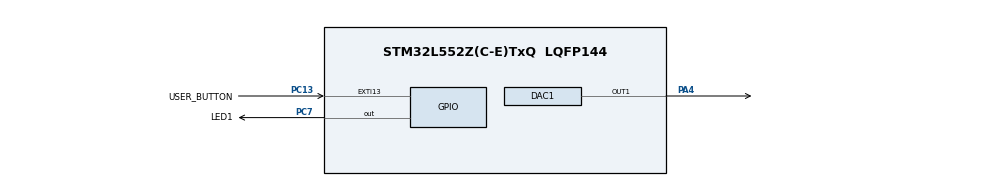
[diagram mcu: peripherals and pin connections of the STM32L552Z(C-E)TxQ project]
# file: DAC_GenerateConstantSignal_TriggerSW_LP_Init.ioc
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DAC1.DAC_HoldTime-DAC_OUT1=(SAMPLE_AND_HOLD_TIMING_HOLD_US    * LSI_FREQUENCY_HZ / 1000000)
DAC1.DAC_RefreshTime-DAC_OUT1=(SAMPLE_AND_HOLD_TIMING_REFRESH_US * LSI_FREQUENCY_HZ / 1000000)
DAC1.DAC_SampleAndHold-DAC_OUT1=DAC_SAMPLEANDHOLD_ENABLE
DAC1.DAC_SampleTime-DAC_OUT1=(SAMPLE_AND_HOLD_TIMING_SAMPLE_US  * LSI_FREQUENCY_HZ / 1000000)
DAC1.DAC_Trigger-DAC_OUT1=DAC_TRIGGER_SOFTWARE
Mcu.Family=STM32L5
Mcu.Name=STM32L552Z(C-E)TxQ
Mcu.Package=LQFP144
Mcu.TrustZone=disable
NVIC.EXTI13_IRQn=true\:3\:0\:true\:false\:true\:true\:true\:true
NVIC.PriorityGroup=NVIC_PRIORITYGROUP_3
PA4.Signal=COMP_DAC11_group
PC13.GPIO_Label=USER_BUTTON
PC13.GPIO_ModeDefaultEXTI=GPIO_MODE_IT_FALLING
PC13.Signal=GPXTI13
PC7.GPIO_Label=LED1
PC7.GPIO_PuPd=GPIO_NOPULL
PC7.Signal=GPIO_Output
ProjectManager.HeapSize=0x200
ProjectManager.StackSize=0x400
ProjectManager.TargetToolchain=EWARM V8.32
RCC.ADCCLockSelection=RCC_ADCCLKSOURCE_SYSCLK
RCC.ADCFreq_Value=110000000
RCC.AHBFreq_Value=110000000
RCC.APB1Freq_Value=110000000
RCC.APB1TimFreq_Value=110000000
RCC.APB2Freq_Value=110000000
RCC.APB2TimFreq_Value=110000000
RCC.CortexFreq_Value=110000000
RCC.HCLKFreq_Value=110000000
RCC.HSE_VALUE=16000000
RCC.HSI48_VALUE=48000000
RCC.HSI_VALUE=16000000
RCC.LSE_VALUE=32768
RCC.MSI_VALUE=4000000
RCC.PLLN=55
RCC.PLLSAI1N=24
RCC.RTCClockSelection=RCC_RTCCLKSOURCE_LSE
RCC.SYSCLKFreq_VALUE=110000000
RCC.SYSCLKSource=RCC_SYSCLKSOURCE_PLLCLK
RCC.USBFreq_Value=48000000
RCC.VCOOutputFreq_Value=220000000
SH.COMP_DAC11_group.0=DAC1_OUT1,DAC_OUT1
VP_ICACHE_VS_ICACHE.Mode=DirectMappedCache
VP_PWR_VS_DBSignals.Mode=DisableDeadBatterySignals
board=custom

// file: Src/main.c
/* USER CODE BEGIN Header */
/**
  ******************************************************************************
  * @file    Examples_LL/DAC/DAC_GenerateConstantSignal_TriggerSW_LP_Init/Src/main.c
  * @author  MCD Application Team
  * @brief   This example describes how to use the DAC peripheral to generate
  *          a constant voltage signal with DAC low power feature
  *          sample-and-hold. To be effective, this mode requires to connect
  *          a capacitor on DAC channel output and sample-and-hold timings
  *          must be tuned in function of capacitor value.
  *          This example is based on the STM32L5xx DAC LL API;
  *          Peripheral initialization done using LL unitary services functions.
  ******************************************************************************
  * @attention
  *
  * Copyright (c) 2019 STMicroelectronics.
  * All rights reserved.
  *
  * This software is licensed under terms that can be found in the LICENSE file
  * in the root directory of this software component.
  * If no LICENSE file comes with this software, it is provided AS-IS.
  *
  ******************************************************************************
  */
/* USER CODE END Header */
#include "main.h"

/* USER CODE BEGIN PD */
/* Definitions of environment analog values */
  /* Value of analog reference voltage (Vref+), connected to analog voltage   */
  /* supply Vdda (unit: mV).                                                  */
  #define VDDA_APPLI                       ((uint32_t)3300)

/* Definitions of data related to this example */
  /* Full-scale digital value with a resolution of 12 bits (voltage range     */
  /* determined by analog voltage references Vref+ and Vref-,                 */
  /* refer to reference manual).                                              */
  #define DIGITAL_SCALE_12BITS             (__LL_DAC_DIGITAL_SCALE(LL_DAC_RESOLUTION_12B))

/* Definitions of data related to DAC low power mode sample-and-hold */
  /* LSI frequency (unit: Hertz) */
  #define LSI_FREQUENCY_HZ                   ((uint32_t)32000)

  /* Definitions of DAC mode sample-and-hold timings (unit: micro-seconds)    */
  /* Note: Timings are set to an arbitrary value, in a real application       */
  /*       they should be tuned in function of capacitor value connected      */
  /*       to DAC output (refer to reference manual).                         */
  /*       If no capacitor is connected on DAC channel output or if           */
  /*       inappropriate timings are set, the voltage appears as              */
  /*       discontinuous.                                                     */
  #define SAMPLE_AND_HOLD_TIMING_SAMPLE_US   ((uint32_t)6000)
  #define SAMPLE_AND_HOLD_TIMING_HOLD_US     ((uint32_t)2000)
  #define SAMPLE_AND_HOLD_TIMING_REFRESH_US  ((uint32_t)5000)

/* USER CODE END PD */

/* USER CODE BEGIN PV */
__IO uint8_t ubButtonPress = 0;
__IO uint8_t ubButtonPressCount = 0;
/* USER CODE END PV */

void SystemClock_Config(void);
static void MX_GPIO_Init(void);
static void MX_ICACHE_Init(void);
static void MX_DAC1_Init(void);
/* USER CODE BEGIN PFP */
void     Activate_DAC(void);
void     LED_On(void);
void     LED_Off(void);
void     LED_Toggle(void);
void     LED_Blinking(uint32_t Period);
void     WaitForUserButtonPress(void);

/* USER CODE END PFP */

int main(void)
{

  /* MCU Configuration--------------------------------------------------------*/

  /* Reset of all peripherals, Initializes the Flash interface and the Systick. */
  LL_APB2_GRP1_EnableClock(LL_APB2_GRP1_PERIPH_SYSCFG);
  LL_APB1_GRP1_EnableClock(LL_APB1_GRP1_PERIPH_PWR);

  /* System interrupt init*/
  NVIC_SetPriorityGrouping(NVIC_PRIORITYGROUP_3);

  /** Disable the internal Pull-Up in Dead Battery pins of UCPD peripheral
  */
  LL_PWR_DisableUCPDDeadBattery();

  /* Configure the system clock */
  SystemClock_Config();

  /* Initialize all configured peripherals */
  MX_GPIO_Init();
  MX_ICACHE_Init();
  MX_DAC1_Init();
  /* USER CODE BEGIN 2 */
/* Wait for User push-button press */
  WaitForUserButtonPress();

  /* Turn-off LED1 */
  LED_Off();

  /* Enable LSI (required for DAC mode sample-and-hold) */
  LL_RCC_LSI_Enable();

  /* Activate DAC channel */
  Activate_DAC();

  /* Turn-on LED1 */
  LED_On();
  /* USER CODE END 2 */

  /* Infinite loop */
  /* USER CODE BEGIN WHILE */
  while (1)
  {
    /* Note: LED state depending and DAC channel output are set into          */
    /*       function "UserButton_Callback()".                                */
    /* USER CODE END WHILE */

  }
}

void SystemClock_Config(void)
{
  LL_FLASH_SetLatency(LL_FLASH_LATENCY_5);
  while(LL_FLASH_GetLatency()!= LL_FLASH_LATENCY_5)
  {
  }

  LL_PWR_SetRegulVoltageScaling(LL_PWR_REGU_VOLTAGE_SCALE0);
  LL_RCC_LSI_Enable();

   /* Wait till LSI is ready */
  while(LL_RCC_LSI_IsReady() != 1)
  {
  }

  LL_RCC_MSI_Enable();

   /* Wait till MSI is ready */
  while(LL_RCC_MSI_IsReady() != 1)
  {
  }

  LL_RCC_MSI_EnableRangeSelection();
  LL_RCC_MSI_SetRange(LL_RCC_MSIRANGE_6);
  LL_RCC_MSI_SetCalibTrimming(0);
  LL_RCC_PLL_ConfigDomain_SYS(LL_RCC_PLLSOURCE_MSI, LL_RCC_PLLM_DIV_1, 55, LL_RCC_PLLR_DIV_2);
  LL_RCC_PLL_EnableDomain_SYS();
  LL_RCC_PLL_Enable();

   /* Wait till PLL is ready */
  while(LL_RCC_PLL_IsReady() != 1)
  {
  }

   /* Intermediate AHB prescaler 2 when target frequency clock is higher than 80 MHz */
   LL_RCC_SetAHBPrescaler(LL_RCC_SYSCLK_DIV_2);

  LL_RCC_SetSysClkSource(LL_RCC_SYS_CLKSOURCE_PLL);

   /* Wait till System clock is ready */
  while(LL_RCC_GetSysClkSource() != LL_RCC_SYS_CLKSOURCE_STATUS_PLL)
  {
  }

  /* Insure 1us transition state at intermediate medium speed clock*/
  for (__IO uint32_t i = (RCC_MAX_FREQUENCY_MHZ >> 1); i !=0; i--);

  LL_RCC_SetAHBPrescaler(LL_RCC_SYSCLK_DIV_1);
  LL_RCC_SetAPB1Prescaler(LL_RCC_APB1_DIV_1);
  LL_RCC_SetAPB2Prescaler(LL_RCC_APB2_DIV_1);

  LL_Init1msTick(110000000);

  LL_SetSystemCoreClock(110000000);
}

static void MX_DAC1_Init(void)
{

  LL_DAC_InitTypeDef DAC_InitStruct = {0};

  LL_GPIO_InitTypeDef GPIO_InitStruct = {0};

  /* Peripheral clock enable */
  LL_APB1_GRP1_EnableClock(LL_APB1_GRP1_PERIPH_DAC1);

  LL_AHB2_GRP1_EnableClock(LL_AHB2_GRP1_PERIPH_GPIOA);
  /**DAC1 GPIO Configuration
  PA4   ------> DAC1_OUT1
  */
  GPIO_InitStruct.Pin = LL_GPIO_PIN_4;
  GPIO_InitStruct.Mode = LL_GPIO_MODE_ANALOG;
  GPIO_InitStruct.Pull = LL_GPIO_PULL_NO;
  LL_GPIO_Init(GPIOA, &GPIO_InitStruct);

  /** DAC channel OUT1 config
  */
  DAC_InitStruct.TriggerSource = LL_DAC_TRIG_SOFTWARE;
  DAC_InitStruct.WaveAutoGeneration = LL_DAC_WAVE_AUTO_GENERATION_NONE;
  DAC_InitStruct.OutputBuffer = LL_DAC_OUTPUT_BUFFER_ENABLE;
  DAC_InitStruct.OutputConnection = LL_DAC_OUTPUT_CONNECT_GPIO;
  DAC_InitStruct.OutputMode = LL_DAC_OUTPUT_MODE_SAMPLE_AND_HOLD;
  LL_DAC_Init(DAC1, LL_DAC_CHANNEL_1, &DAC_InitStruct);
  LL_DAC_EnableTrigger(DAC1, LL_DAC_CHANNEL_1);
  LL_DAC_SetSampleAndHoldSampleTime(DAC1, LL_DAC_CHANNEL_1, (SAMPLE_AND_HOLD_TIMING_SAMPLE_US * LSI_FREQUENCY_HZ / 1000000));
  LL_DAC_SetSampleAndHoldHoldTime(DAC1, LL_DAC_CHANNEL_1, (SAMPLE_AND_HOLD_TIMING_HOLD_US * LSI_FREQUENCY_HZ / 1000000));
  LL_DAC_SetSampleAndHoldRefreshTime(DAC1, LL_DAC_CHANNEL_1, (SAMPLE_AND_HOLD_TIMING_REFRESH_US * LSI_FREQUENCY_HZ / 1000000));

}

static void MX_ICACHE_Init(void)
{

  /** Enable instruction cache in 1-way (direct mapped cache)
  */
  LL_ICACHE_SetMode(LL_ICACHE_1WAY);
  LL_ICACHE_Enable();

}

static void MX_GPIO_Init(void)
{
  LL_EXTI_InitTypeDef EXTI_InitStruct = {0};
  LL_GPIO_InitTypeDef GPIO_InitStruct = {0};

  /* GPIO Ports Clock Enable */
  LL_AHB2_GRP1_EnableClock(LL_AHB2_GRP1_PERIPH_GPIOC);
  LL_AHB2_GRP1_EnableClock(LL_AHB2_GRP1_PERIPH_GPIOA);

  /**/
  LL_GPIO_ResetOutputPin(LED1_GPIO_Port, LED1_Pin);

  /**/
  LL_EXTI_SetEXTISource(LL_EXTI_EXTI_PORTC, LL_EXTI_EXTI_LINE13);

  /**/
  EXTI_InitStruct.Line_0_31 = LL_EXTI_LINE_13;
  EXTI_InitStruct.Line_32_63 = LL_EXTI_LINE_NONE;
  EXTI_InitStruct.LineCommand = ENABLE;
  EXTI_InitStruct.Mode = LL_EXTI_MODE_IT;
  EXTI_InitStruct.Trigger = LL_EXTI_TRIGGER_FALLING;
  LL_EXTI_Init(&EXTI_InitStruct);

  /**/
  LL_GPIO_SetPinPull(USER_BUTTON_GPIO_Port, USER_BUTTON_Pin, LL_GPIO_PULL_NO);

  /**/
  LL_GPIO_SetPinMode(USER_BUTTON_GPIO_Port, USER_BUTTON_Pin, LL_GPIO_MODE_INPUT);

  /**/
  GPIO_InitStruct.Pin = LED1_Pin;
  GPIO_InitStruct.Mode = LL_GPIO_MODE_OUTPUT;
  GPIO_InitStruct.Speed = LL_GPIO_SPEED_FREQ_LOW;
  GPIO_InitStruct.OutputType = LL_GPIO_OUTPUT_PUSHPULL;
  GPIO_InitStruct.Pull = LL_GPIO_PULL_NO;
  LL_GPIO_Init(LED1_GPIO_Port, &GPIO_InitStruct);

  /* EXTI interrupt init*/
  NVIC_SetPriority(EXTI13_IRQn, NVIC_EncodePriority(NVIC_GetPriorityGrouping(),3, 0));
  NVIC_EnableIRQ(EXTI13_IRQn);

}

/* USER CODE BEGIN 4 */

/**
  * @brief  Perform DAC activation procedure to make it ready to generate
  *         a voltage (DAC instance: DAC1).
  * @note   Operations:
  *         - Enable DAC instance channel
  *         - Wait for DAC instance channel startup time
  * @param  None
  * @retval None
  */
void Activate_DAC(void)
{
  __IO uint32_t wait_loop_index = 0;

  /* Enable DAC channel */
  LL_DAC_Enable(DAC1, LL_DAC_CHANNEL_1);

  /* Delay for DAC channel voltage settling time from DAC channel startup.    */
  /* Compute number of CPU cycles to wait for, from delay in us.              */
  /* Note: Variable divided by 2 to compensate partially                      */
  /*       CPU processing cycles (depends on compilation optimization).       */
  /* Note: If system core clock frequency is below 200kHz, wait time          */
  /*       is only a few CPU processing cycles.                               */
  wait_loop_index = ((LL_DAC_DELAY_STARTUP_VOLTAGE_SETTLING_US * (SystemCoreClock / (100000 * 2))) / 10);
  while(wait_loop_index != 0)
  {
    wait_loop_index--;
  }

  /* Enable DAC channel trigger */
  /* Note: DAC channel conversion can start from trigger enable:              */
  /*       - if DAC channel trigger source is set to SW:                      */
  /*         DAC channel conversion will start after trig order               */
  /*         using function "LL_DAC_TrigSWConversion()".                      */
  /*       - if DAC channel trigger source is set to external trigger         */
  /*         (timer, ...):                                                    */
  /*         DAC channel conversion can start immediately                     */
  /*         (after next trig order from external trigger)                    */
  LL_DAC_EnableTrigger(DAC1, LL_DAC_CHANNEL_1);
}

/**
  * @brief  Turn-on LED1.
  * @param  None
  * @retval None
  */
void LED_On(void)
{
  /* Turn LED1 on */
  LL_GPIO_SetOutputPin(LED1_GPIO_Port, LED1_Pin);
}

/**
  * @brief  Turn-off LED1.
  * @param  None
  * @retval None
  */
void LED_Off(void)
{
  /* Turn LED1 off */
  LL_GPIO_ResetOutputPin(LED1_GPIO_Port, LED1_Pin);
}

/**
  * @brief  Toggle LED1.
  * @param  None
  * @retval None
  */
void LED_Toggle(void)
{
  /* Toggle LED1 */
  LL_GPIO_TogglePin(LED1_GPIO_Port, LED1_Pin);
}

/**
  * @brief  Set LED1 to Blinking mode for an infinite loop (toggle period based on value provided as input parameter).
  * @param  Period : Period of time (in ms) between each toggling of LED
  *   This parameter can be user defined values. Pre-defined values used in that example are :
  *     @arg LED_BLINK_FAST : Fast Blinking
  *     @arg LED_BLINK_SLOW : Slow Blinking
  *     @arg LED_BLINK_ERROR : Error specific Blinking
  * @retval None
  */
void LED_Blinking(uint32_t Period)
{
  /* Turn LED1 on */
  LL_GPIO_SetOutputPin(LED1_GPIO_Port, LED1_Pin);

  /* Toggle IO in an infinite loop */
  while (1)
  {
    LL_GPIO_TogglePin(LED1_GPIO_Port, LED1_Pin);
    LL_mDelay(Period);
  }
}

/**
  * @brief  Wait for User push-button press to start transfer.
  * @param  None
  * @retval None
  */
void WaitForUserButtonPress(void)
{
  while (ubButtonPress == 0)
  {
    LL_GPIO_TogglePin(LED1_GPIO_Port, LED1_Pin);
    LL_mDelay(LED_BLINK_FAST);
  }
}

/******************************************************************************/
/*   USER IRQ HANDLER TREATMENT                                               */
/******************************************************************************/
/**
  * @brief  Function to manage IRQ Handler
  * @param  None
  * @retval None
  */
void UserButton_Callback(void)
{
  uint32_t tmp_dac_value = 0;

  /* On the first press on user button, update only user button variable      */
  /* to manage waiting function.                                              */
  /* Then, on next presses on user button, update DAC settings.               */
  if(ubButtonPress == 0)
  {
    /* Update User push-button variable : to be checked in waiting loop in main program */
    ubButtonPress = 1;
  }
  else
  {
    ubButtonPressCount++;

    /* Set value for DAC output */
    if(ubButtonPressCount < 4)
    {
      /* Increase amplitude by a quarter each time button is pushed */
      tmp_dac_value = DIGITAL_SCALE_12BITS * ubButtonPressCount/4;

      /* Toggle LED1 */
      LED_Toggle();
    }
    else
    {
      /* Final amplitude: end of example */
      tmp_dac_value = DIGITAL_SCALE_12BITS;

      /* Turn-on LED1 */
      LED_On();
    }

    /* Set the data to be loaded in the data holding register */
    LL_DAC_ConvertData12RightAligned(DAC1, LL_DAC_CHANNEL_1, tmp_dac_value);

    /* Trig DAC conversion by software */
    LL_DAC_TrigSWConversion(DAC1, LL_DAC_CHANNEL_1);
  }
}

/**
  * @brief  DAC underrun interruption callback
  * @note   This function is executed when DAC channel underrun error occurs.
  * @retval None
  */
void DacUnderrunError_Callback(void)
{
  /* Note: Disable DAC interruption that caused this error before entering in */
  /*       infinite loop below.                                               */

  /* Disable interruption DAC channel1 underrun */
  LL_DAC_DisableIT_DMAUDR1(DAC1);

  /* Error from ADC */
  LED_Blinking(LED_BLINK_ERROR);
}

/* USER CODE END 4 */

void Error_Handler(void)
{
  while(1)
  {
  }
}
